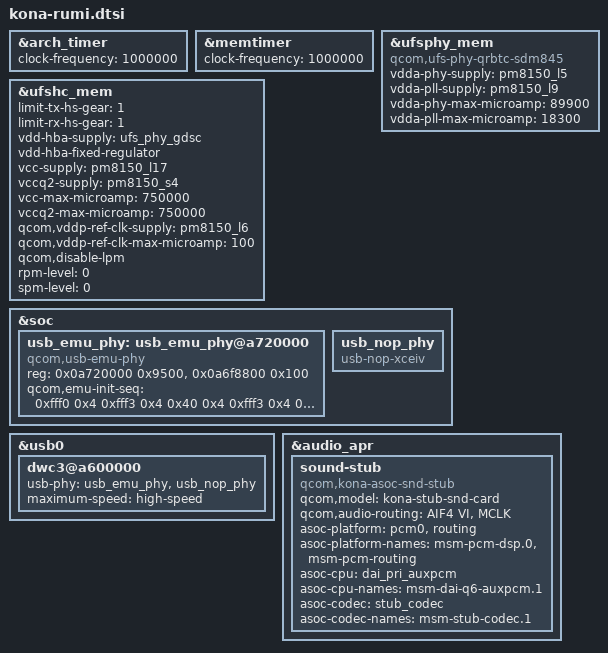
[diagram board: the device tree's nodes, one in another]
// SPDX-License-Identifier: GPL-2.0
/*
 * Copyright (c) 2018, The Linux Foundation. All rights reserved.
 */

#include "kona-pmic-overlay.dtsi"
#include "msm-audio-lpass.dtsi"

&arch_timer {
	clock-frequency = <1000000>;
};

&memtimer {
	clock-frequency = <1000000>;
};

&ufsphy_mem {
	compatible = "qcom,ufs-phy-qrbtc-sdm845";

	vdda-phy-supply = <&pm8150_l5>;
	vdda-pll-supply = <&pm8150_l9>;
	vdda-phy-max-microamp = <89900>;
	vdda-pll-max-microamp = <18300>;

	status = "ok";
};

&ufshc_mem {
	limit-tx-hs-gear = <1>;
	limit-rx-hs-gear = <1>;

	vdd-hba-supply = <&ufs_phy_gdsc>;
	vdd-hba-fixed-regulator;
	vcc-supply = <&pm8150_l17>;
	vccq2-supply = <&pm8150_s4>;
	vcc-max-microamp = <750000>;
	vccq2-max-microamp = <750000>;

	qcom,vddp-ref-clk-supply = <&pm8150_l6>;
	qcom,vddp-ref-clk-max-microamp = <100>;

	qcom,disable-lpm;
	rpm-level = <0>;
	spm-level = <0>;
	status = "ok";
};

&soc {
	usb_emu_phy: usb_emu_phy@a720000 {
		compatible = "qcom,usb-emu-phy";
		reg = <0x0a720000 0x9500>,
		      <0x0a6f8800 0x100>;
		reg-names = "base", "qscratch_base";

		qcom,emu-init-seq = <0xfff0 0x4
				     0xfff3 0x4
				     0x40 0x4
				     0xfff3 0x4
				     0xfff0 0x4
				     0x100000 0x20
				     0x0 0x20
				     0x1a0 0x20
				     0x100000 0x3c
				     0x0 0x3c
				     0x10060 0x3c
				     0x0 0x4>;
	};

	usb_nop_phy: usb_nop_phy {
		compatible = "usb-nop-xceiv";
	};
};

&usb0 {
	dwc3@a600000 {
		usb-phy = <&usb_emu_phy>, <&usb_nop_phy>;
		maximum-speed = "high-speed";
	};
};

&audio_apr {
	sound-stub {
		compatible = "qcom,kona-asoc-snd-stub";
		qcom,model = "kona-stub-snd-card";

		qcom,audio-routing =
			"AIF4 VI", "MCLK";

		asoc-platform = <&pcm0>, <&routing>;
		asoc-platform-names = "msm-pcm-dsp.0", "msm-pcm-routing";
		asoc-cpu = <&dai_pri_auxpcm>;
		asoc-cpu-names = "msm-dai-q6-auxpcm.1";
		asoc-codec = <&stub_codec>;
		asoc-codec-names = "msm-stub-codec.1";
	};
};
